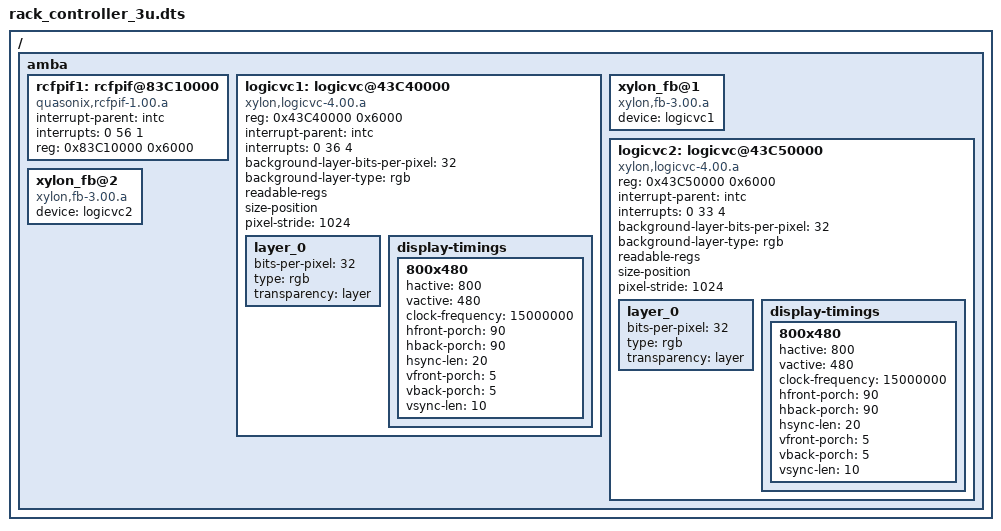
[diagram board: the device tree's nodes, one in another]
/dts-v1/;

/include/ "skeleton.dtsi"
/include/ "rack_controller.dtsi"

/ {
  amba {
	rcfpif1: rcfpif@83C10000 {
		compatible = "quasonix,rcfpif-1.00.a";
		interrupt-parent = <&intc>;
		interrupts = < 0 56 1 >;
		reg = <0x83C10000 0x6000>;
	};

	logicvc1: logicvc@43C40000 {
		compatible = "xylon,logicvc-4.00.a";
		reg = <0x43C40000 0x6000>;
		interrupt-parent = <&intc>;
		interrupts = < 0 36 4 >;

		background-layer-bits-per-pixel = <32>;
		background-layer-type = "rgb";
		readable-regs;
		size-position;
		pixel-stride = <1024>;

		layer_0 {
			//address = <0x3E000000>;
  			//buffer-offset = <1024>;
			bits-per-pixel = <32>;
			type = "rgb";
			transparency = "layer";
		};

		display-timings {
			800x480 {
				hactive = <800>;
				vactive = <480>;
				clock-frequency = <15000000>;
				hfront-porch = <90>;
				hback-porch = <90>;
				hsync-len = <20>;
				vfront-porch = <5>;
				vback-porch = <5>;
				vsync-len = <10>;
				};
			};
		};

	xylon_fb@1 {
		 compatible = "xylon,fb-3.00.a";
		 device = <&logicvc1>;
		 //video-mode = "800x480";
		 } ;

	logicvc2: logicvc@43C50000 {
		compatible = "xylon,logicvc-4.00.a";
		reg = <0x43C50000 0x6000>;
		interrupt-parent = <&intc>;
		interrupts = < 0 33 4 >;

		background-layer-bits-per-pixel = <32>;
		background-layer-type = "rgb";
		readable-regs;
		size-position;
		pixel-stride = <1024>;

		layer_0 {
			//address = <0x3F000000>;
			//buffer-offset = <1024>;
			bits-per-pixel = <32>;
			type = "rgb";
			transparency = "layer";
		};

		display-timings {
			800x480 {
				hactive = <800>;
				vactive = <480>;
				clock-frequency = <15000000>;
				hfront-porch = <90>;
				hback-porch = <90>;
				hsync-len = <20>;
				vfront-porch = <5>;
				vback-porch = <5>;
				vsync-len = <10>;
				};
			};
		};

	xylon_fb@2 {
		 compatible = "xylon,fb-3.00.a";
		 device = <&logicvc2>;
		 //video-mode = "800x480";
		 } ;
	};

};

	
